# MKL28T7_CORE1 register map
Vendor: Freescale Semiconductor, Inc.; Series: Kinetis_L; File version: 1.6
CPU: CM0PLUS r0p0, little endian, no MPU, no FPU, VTOR, 2 interrupt priority bits
Registers are 32-bit, read-write, reset 0x0 unless marked. A register's access mark holds for its fields unless they carry their own. Offsets are from the block's base; [hi:lo] are bit positions; 'fields as' and 'values as' point back to an identical list.

## TSTMR0 — Timestamp Timer
Base 0x400750F0; register names take the prefix TSTMR0_
0x00 L ro — Time Stamp Timer Register Low
  [31:0] VALUE — Time Stamp Timer Low
0x04 H ro — Time Stamp Timer Register High
  [23:0] VALUE — Time Stamp Timer High

## TSTMR1 — Timestamp Timer
Base 0x400F50F0; register names take the prefix TSTMR1_
Registers as TSTMR0.

## WDOG0 — Watchdog timer
Base 0x40076000; register names take the prefix WDOG0_
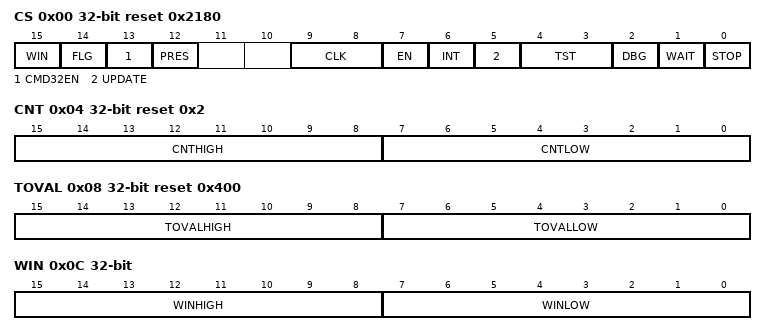
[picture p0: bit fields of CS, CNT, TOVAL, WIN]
0x00 CS reset 0x2180 — Watchdog Control and Status Register
  [15] WIN — Watchdog Window
    0=Window mode disabled; 1=Window mode enabled
  [14] FLG — Watchdog Interrupt Flag
    0=No interrupt occurred; 1=An interrupt occurred
  [13] CMD32EN — Enables or disables WDOG support for 32-bit (or 16-bit or 8-bit) refresh/unlock command write words
    0=Disables support for 32-bit (or 16-bit or 8-bit) refresh/unlock command write words; 1=Enables support for 32-bit (or 16-bit or 8-bit) refresh/unlock command write words
  [12] PRES — Watchdog Prescalar
    0=256 prescalar disabled; 1=256 prescalar enabled
  [9:8] CLK — Watchdog Clock
    0=Bus clock; 1=Internal low-power oscillator (LPOCLK); 2=8 MHz internal reference clock; 3=External clock source
  [7] EN — Watchdog Enable
    0=Watchdog disabled; 1=Watchdog enabled
  [6] INT — Watchdog Interrupt
    0=Watchdog interrupts are disabled. Watchdog resets are not delayed.; 1=Watchdog interrupts are enabled. Watchdog resets are delayed by 128 bus clocks from the interrupt vector fetch.
  [5] UPDATE — Allow updates
    0=Updates not allowed. After the initial configuration, the watchdog cannot be later modified without forcing a reset.; 1=Updates allowed. Software can modify the watchdog configuration registers within 128 bus clocks after performing the unlock write sequence.
  [4:3] TST — Watchdog Test
    0=Watchdog test mode disabled; 1=Watchdog user mode enabled. (Watchdog test mode disabled.) After testing the watchdog, software should use this setting to indicate that the watchdog is functioning normally in user mode.; 2=Watchdog test mode enabled, only the low byte is used. CNT[CNTLOW] is compared with TOVAL[TOVALLOW].; 3=Watchdog test mode enabled, only the high byte is used. CNT[CNTHIGH] is compared with TOVAL[TOVALHIGH].
  [2] DBG — Debug Enable
    0=Watchdog disabled in chip debug mode; 1=Watchdog enabled in chip debug mode
  [1] WAIT — Wait Enable
    0=Watchdog disabled in chip wait mode; 1=Watchdog enabled in chip wait mode
  [0] STOP — Stop Enable
    0=Watchdog disabled in chip stop mode; 1=Watchdog enabled in chip stop mode
0x04 CNT reset 0x2 — Watchdog Counter Register
  [15:8] CNTHIGH — High byte of the Watchdog Counter
  [7:0] CNTLOW — Low byte of the Watchdog Counter
0x08 TOVAL reset 0x400 — Watchdog Timeout Value Register
  [15:8] TOVALHIGH — High byte of the timeout value;
  [7:0] TOVALLOW — Low byte of the timeout value
0x0C WIN — Watchdog Window Register
  [15:8] WINHIGH — High byte of Watchdog Window
  [7:0] WINLOW — Low byte of Watchdog Window

## WDOG1 — Watchdog timer
Base 0x400F6000; register names take the prefix WDOG1_
Registers as WDOG0.

## CRC — Cyclic Redundancy Check
Base 0x40078000; register names take the prefix CRC_
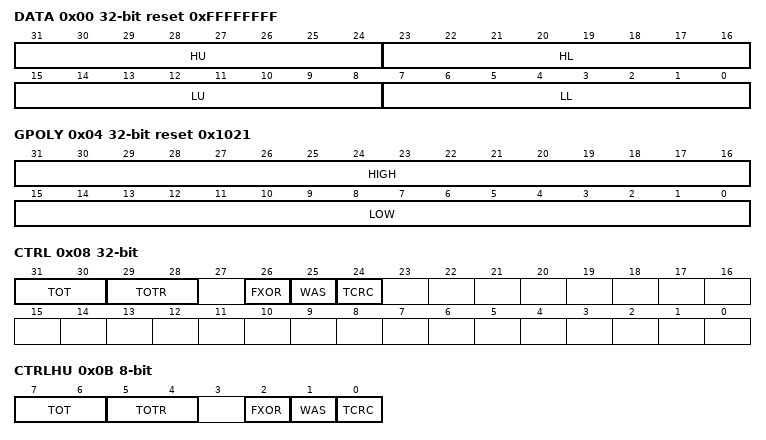
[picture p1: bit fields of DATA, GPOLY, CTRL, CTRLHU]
0x00 DATA reset 0xFFFFFFFF (CRC view) — CRC Data register
  [31:24] HU — CRC High Upper Byte
  [23:16] HL — CRC High Lower Byte
  [15:8] LU — CRC Low Upper Byte
  [7:0] LL — CRC Low Lower Byte
0x00 DATAL 16-bit reset 0xFFFF (CRC view) — CRC_DATAL register.
  [15:0] DATAL — DATAL stores the lower 16 bits of the 16/32 bit CRC
0x00 DATALL 8-bit reset 0xFF (CRC view) — CRC_DATALL register.
  [7:0] DATALL — CRCLL stores the first 8 bits of the 32 bit DATA
0x01 DATALU 8-bit reset 0xFF — CRC_DATALU register.
  [7:0] DATALU — DATALL stores the second 8 bits of the 32 bit CRC
0x02 DATAH 16-bit reset 0xFFFF (CRC view) — CRC_DATAH register.
  [15:0] DATAH — DATAH stores the high 16 bits of the 16/32 bit CRC
0x02 DATAHL 8-bit reset 0xFF (CRC view) — CRC_DATAHL register.
  [7:0] DATAHL — DATAHL stores the third 8 bits of the 32 bit CRC
0x03 DATAHU 8-bit reset 0xFF — CRC_DATAHU register.
  [7:0] DATAHU — DATAHU stores the fourth 8 bits of the 32 bit CRC
0x04 GPOLY reset 0x1021 (CRC view) — CRC Polynomial register
  [31:16] HIGH — High Polynominal Half-word
  [15:0] LOW — Low Polynominal Half-word
0x04 GPOLYL 16-bit reset 0xFFFF (CRC view) — CRC_GPOLYL register.
  [15:0] GPOLYL — POLYL stores the lower 16 bits of the 16/32 bit CRC polynomial value
0x04 GPOLYLL 8-bit reset 0xFF (CRC view) — CRC_GPOLYLL register.
  [7:0] GPOLYLL — POLYLL stores the first 8 bits of the 32 bit CRC
0x05 GPOLYLU 8-bit reset 0xFF — CRC_GPOLYLU register.
  [7:0] GPOLYLU — POLYLL stores the second 8 bits of the 32 bit CRC
0x06 GPOLYH 16-bit reset 0xFFFF (CRC view) — CRC_GPOLYH register.
  [15:0] GPOLYH — POLYH stores the high 16 bits of the 16/32 bit CRC polynomial value
0x06 GPOLYHL 8-bit reset 0xFF (CRC view) — CRC_GPOLYHL register.
  [7:0] GPOLYHL — POLYHL stores the third 8 bits of the 32 bit CRC
0x07 GPOLYHU 8-bit reset 0xFF — CRC_GPOLYHU register.
  [7:0] GPOLYHU — POLYHU stores the fourth 8 bits of the 32 bit CRC
0x08 CTRL — CRC Control register
  [31:30] TOT — Type Of Transpose For Writes
    0=No transposition; 1=Bits in bytes are transposed; bytes are not transposed; 2=Both bits in bytes and bytes are transposed; 3=Only bytes are transposed; no bits in a byte are transposed
  [29:28] TOTR — Type Of Transpose For Read
    values as TOT
  [26] FXOR — Complement Read Of CRC Data Register
    0=No XOR on reading; 1=Invert or complement the read value of the CRC Data register
  [25] WAS — Write CRC Data Register As Seed
    0=Writes to the CRC data register are data values; 1=Writes to the CRC data register are seed values
  [24] TCRC — Width of CRC protocol.
    0=16-bit CRC protocol; 1=32-bit CRC protocol
0x0B CTRLHU 8-bit — CRC_CTRLHU register.
  [7:6] TOT
    0=No Transposition; 1=Bits in bytes are transposed, bytes are not transposed; 2=Both bits in bytes and bytes are transposed; 3=Only bytes are transposed; no bits in a byte are transposed
  [5:4] TOTR
    values as TOT
  [2] FXOR
    0=No XOR on reading; 1=Invert or complement the read value of CRC data register
  [1] WAS
    0=Writes to CRC data register are data values; 1=Writes to CRC data reguster are seed values
  [0] TCRC
    0=16-bit CRC protocol; 1=32-bit CRC protocol
